# GPIOB_1.0 register map
Vendor: Texas Instruments
Peripheral module from a debugger description file (folder mspm0g1x0x_g3x0x).
Registers are 32-bit, read-write, no defined reset value unless marked. A register's access mark holds for its fields unless they carry their own. Offsets are as the file gives them; lines under a group give offsets from that group; [hi:lo] are bit positions; {n}, {i} and the like mark numbered series; 'fields as' and 'values as' point back to an identical list; <NAME> marks a mode.

## GPIOB
0x400 GPIOB_FSUB_0 — Subsciber Port 0
  [3:0] CHANID — 0 = disconnected. 1-15 = connected to channelID = CHANID.
    0=MNIMUM (0 is an allowed value, signifying that the event is unconnected); 0=UNCONNECTED (A value of 0 specifies that the event is not connected); 15=MAXIMUM (Consult your device datasheet as the actual allowed maximum may be less than 15.)
0x404 GPIOB_FSUB_1 — Subscriber Port 1
  fields as GPIOB_FSUB_0
0x444 GPIOB_FPUB_0 — Publisher Port 0
  fields as GPIOB_FSUB_0
0x448 GPIOB_FPUB_1 — Publisher Port 1
  fields as GPIOB_FSUB_0
0x800 GPIOB_GPRCM group
  0x00 GPIOB_PWREN — Power enable
    [0] ENABLE — Enable the power
      0=DISABLE (Disable Power); 1=ENABLE (Enable Power)
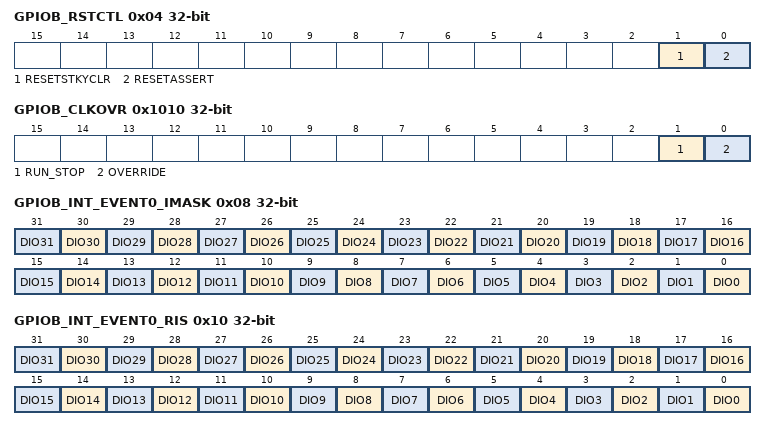
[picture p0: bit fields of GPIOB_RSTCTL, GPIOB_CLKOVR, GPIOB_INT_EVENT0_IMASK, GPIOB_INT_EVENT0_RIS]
  0x04 GPIOB_RSTCTL — Reset Control
    [1] RESETSTKYCLR — Clear the RESETSTKY bit in the STAT register
      0=NOP (Writing 0 has no effect); 1=CLR (Clear reset sticky bit)
    [0] RESETASSERT — Assert reset to the peripheral
      0=NOP (Writing 0 has no effect); 1=ASSERT (Assert reset)
  0x14 GPIOB_STAT ro — Status Register
    [16] RESETSTKY — This bit indicates, if the peripheral was reset, since this bit was cleared by RESETSTKYCLR in the RSTCTL register
      0=NORES (The peripheral has not been reset since this bit was last cleared by RESETSTKYCLR in the RSTCTL register); 1=RESET (The peripheral was reset since the last bit clear)
0x1010 GPIOB_CLKOVR — Clock Override
  [1] RUN_STOP — If [OVERRIDE] is enabled, this register is used to manually control the peripheral's clock request to the system
    0=RUN (Run/ungate functional clock); 1=STOP (Stop/gate functional clock)
  [0] OVERRIDE — Unlocks the functionality of [RUN_STOP] to override the automatic peripheral clock request
    0=DISABLED (Override disabled); 1=ENABLED (Override enabled)
0x1018 GPIOB_PDBGCTL — Peripheral Debug Control
  [0] FREE — Free run control
    0=STOP (The peripheral freezes functionality while the Core Halted input is asserted and resumes when it is deasserted.); 1=RUN (The peripheral ignores the state of the Core Halted input)
0x1020 GPIOB_INT_EVENT0 group
  0x00 GPIOB_INT_EVENT0_IIDX ro — Interrupt index
    [7:0] STAT — Interrupt index status
      0=NO_INTR (No bit is set means there is no pending interrupt request); {v}=DIO{v-1} (DIO{v-1} interrupt) (v=1..32)
  0x08 GPIOB_INT_EVENT0_IMASK — Interrupt mask
    [all] fields
      0=CLR (Event is masked); 1=SET (Event is unmasked)
    [n] DIO{n} (n=0..31) — DIO{n} event mask
  0x10 GPIOB_INT_EVENT0_RIS — Raw interrupt status
    [n] DIO{n} (n=0..31) — DIO{n} event
      0=CLR (DIO{n} event did not occur); 1=SET (DIO{n} event occurred)
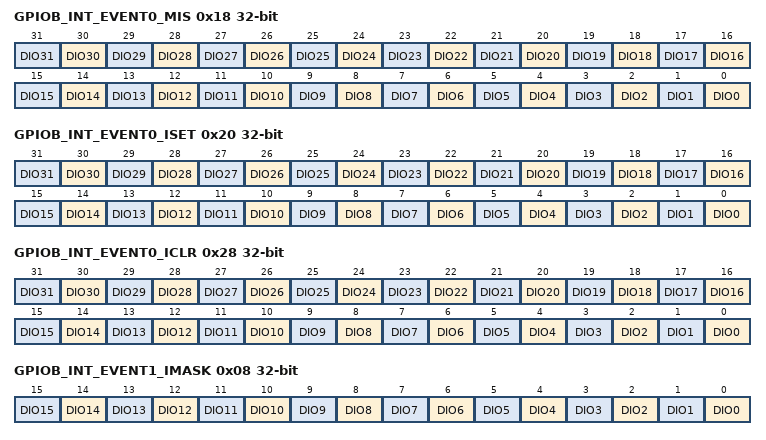
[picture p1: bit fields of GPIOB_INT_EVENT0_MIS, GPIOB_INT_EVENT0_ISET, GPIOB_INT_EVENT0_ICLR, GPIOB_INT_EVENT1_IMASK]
  0x18 GPIOB_INT_EVENT0_MIS — Masked interrupt status
    fields as GPIOB_INT_EVENT0.GPIOB_INT_EVENT0_RIS
  0x20 GPIOB_INT_EVENT0_ISET — Interrupt set
    [n] DIO{n} (n=0..31) — DIO{n} event
      0=NO_EFFECT; 1=SET (Sets DIO{n} in RIS register)
  0x28 GPIOB_INT_EVENT0_ICLR — Interrupt clear
    [n] DIO{n} (n=0..31) — DIO{n} event
      0=NO_EFFECT; 1=CLR (Clears DIO{n} in RIS register)
0x1050 GPIOB_INT_EVENT1 group
  0x00 GPIOB_INT_EVENT1_IIDX ro — Interrupt index
    [7:0] STAT — Interrupt index status
      0=NO_INTR (No bit is set means there is no pending interrupt request); {v}=DIO{v-1} (DIO{v-1} interrupt) (v=1..16)
  0x08 GPIOB_INT_EVENT1_IMASK — Interrupt mask
    [all] fields
      0=CLR (Event is masked); 1=SET (Event is unmasked)
    [n] DIO{n} (n=0..15) — DIO{n} event mask
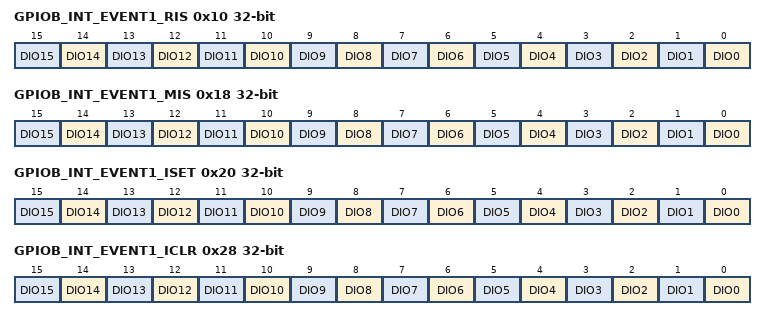
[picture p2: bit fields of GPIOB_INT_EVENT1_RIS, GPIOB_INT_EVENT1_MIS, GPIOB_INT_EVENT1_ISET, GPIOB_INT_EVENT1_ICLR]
  0x10 GPIOB_INT_EVENT1_RIS — Raw interrupt status
    [n] DIO{n} (n=0..15) — DIO{n} event
      values as GPIOB_INT_EVENT0.GPIOB_INT_EVENT0_RIS.DIO0
  0x18 GPIOB_INT_EVENT1_MIS — Masked interrupt status
    fields as GPIOB_INT_EVENT1.GPIOB_INT_EVENT1_RIS
  0x20 GPIOB_INT_EVENT1_ISET — Interrupt set
    [n] DIO{n} (n=0..15) — DIO{n} event
      0=NO_EFFECT; 1=SET (Sets DIO{n} in RIS register)
  0x28 GPIOB_INT_EVENT1_ICLR — Interrupt clear
    [n] DIO{n} (n=0..15) — DIO{n} event
      0=NO_EFFECT; 1=CLR (Clears DIO{n} in RIS register)
0x1080 GPIOB_INT_EVENT2 group
  0x00 GPIOB_INT_EVENT2_IIDX ro — Interrupt index
    [7:0] STAT — Interrupt index status
      0=NO_INTR (No bit is set means there is no pending interrupt request); {v}=DIO{v+15} (DIO{v-1} interrupt) (v=1..16)
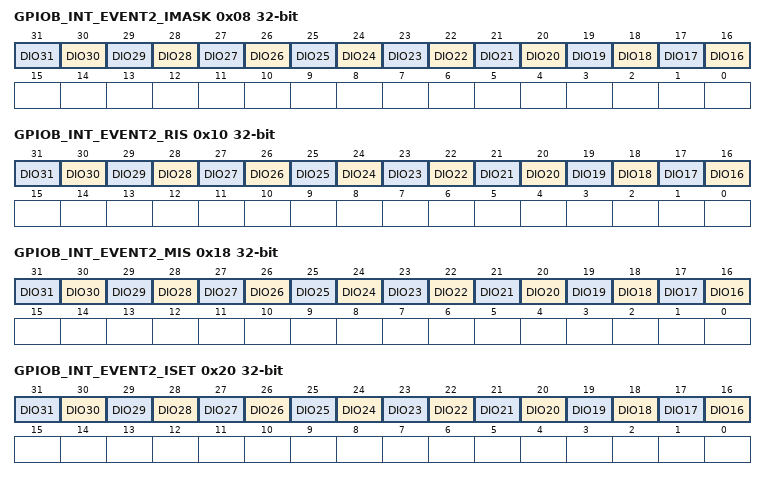
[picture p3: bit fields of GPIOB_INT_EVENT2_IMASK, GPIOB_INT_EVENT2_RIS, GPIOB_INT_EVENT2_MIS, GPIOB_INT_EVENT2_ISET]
  0x08 GPIOB_INT_EVENT2_IMASK — Interrupt mask
    [all] fields
      0=CLR (Event is masked); 1=SET (Event is unmasked)
    [n] DIO{n} (n=16..31) — DIO{n} event mask
  0x10 GPIOB_INT_EVENT2_RIS — Raw interrupt status
    [n] DIO{n} (n=16..31) — DIO{n} event
      values as GPIOB_INT_EVENT0.GPIOB_INT_EVENT0_RIS.DIO0
  0x18 GPIOB_INT_EVENT2_MIS — Masked interrupt status
    fields as GPIOB_INT_EVENT2.GPIOB_INT_EVENT2_RIS
  0x20 GPIOB_INT_EVENT2_ISET — Interrupt set
    [n] DIO{n} (n=16..31) — DIO{n} event
      0=NO_EFFECT; 1=SET (Sets DIO{n} in RIS register)
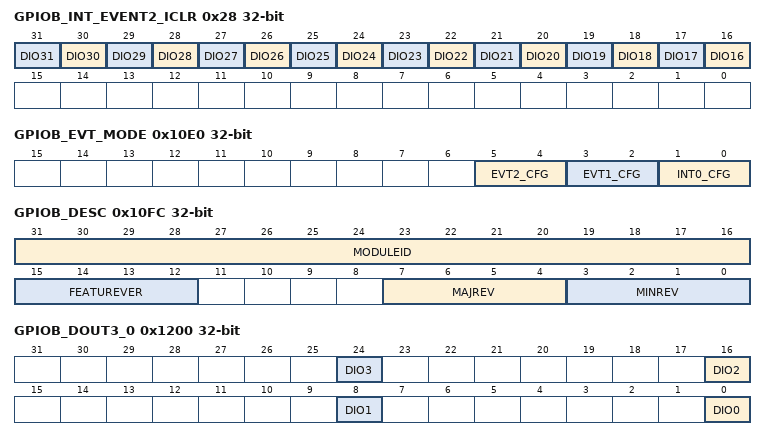
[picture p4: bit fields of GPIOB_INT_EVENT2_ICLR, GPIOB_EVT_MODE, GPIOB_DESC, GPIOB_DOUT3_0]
  0x28 GPIOB_INT_EVENT2_ICLR — Interrupt clear
    [n] DIO{n} (n=16..31) — DIO{n} event
      0=NO_EFFECT; 1=CLR (Clears DIO{n} in RIS register)
0x10E0 GPIOB_EVT_MODE ro — Event Mode
  [all] fields
    0=DISABLE (The interrupt or event line is disabled.); 1=SOFTWARE (The interrupt or event line is in software mode. Software must clear the RIS.); 2=HARDWARE (The interrupt or event line is in hardware mode. The hardware (another module) clears automatically the associated RIS flag.)
  [5:4] EVT2_CFG — Event line mode select for event corresponding to [IPSTANDARD.INT_EVENT2]
  [3:2] EVT1_CFG — Event line mode select for event corresponding to [IPSTANDARD.INT_EVENT1]
  [1:0] INT0_CFG — Event line mode select for event corresponding to [IPSTANDARD.INT_EVENT0]
0x10FC GPIOB_DESC — Module Description
  [31:16] MODULEID — Module identification contains a unique peripheral identification number. The assignments are maintained in a central database for all of the platform modules to ensure uniqueness.
    0=MINIMUM (Smallest value); 0xFFFF=MAXIMUM (Highest possible value)
  [15:12] FEATUREVER — Feature Set for the module *instance*
    0=MINIMUM (Smallest value); 15=MAXIMUM (Highest possible value)
  [7:4] MAJREV — Major rev of the IP
    values as FEATUREVER
  [3:0] MINREV — Minor rev of the IP
    values as FEATUREVER
0x1200 GPIOB_DOUT3_0 — Data output 3 to 0
  [all] fields
    0=ZERO (Output is set to 0); 1=ONE (Output is set to 1)
  [8n] DIO{n} (n=0..3) — This bit sets the value of the pin configured as DIO{n} when the output is enabled through DOE31_0 register.
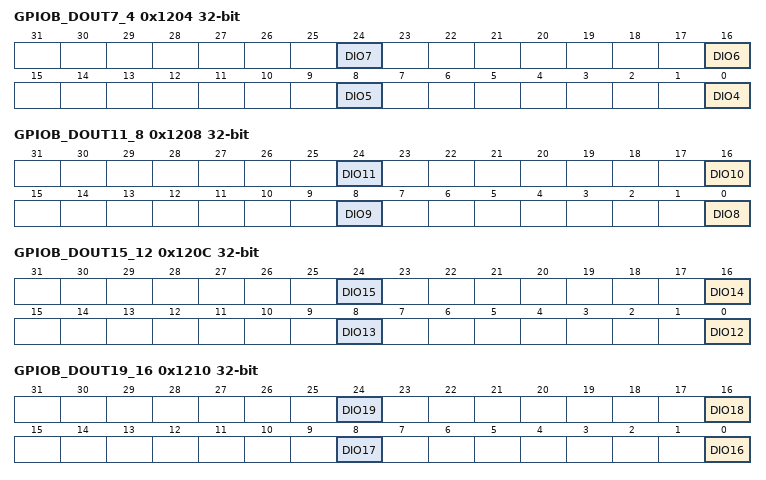
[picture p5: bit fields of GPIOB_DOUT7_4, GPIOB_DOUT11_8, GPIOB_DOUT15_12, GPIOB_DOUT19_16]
0x1204 GPIOB_DOUT7_4 — Data output 7 to 4
  [all] fields
    0=ZERO (Output is set to 0); 1=ONE (Output is set to 1)
  [8n-32] DIO{n} (n=4..7) — This bit sets the value of the pin configured as DIO{n} when the output is enabled through DOE31_0 register.
0x1208 GPIOB_DOUT11_8 — Data output 11 to 8
  [all] fields
    0=ZERO (Output is set to 0); 1=ONE (Output is set to 1)
  [8n-64] DIO{n} (n=8..11) — This bit sets the value of the pin configured as DIO{n} when the output is enabled through DOE31_0 register.
0x120C GPIOB_DOUT15_12 — Data output 15 to 12
  [all] fields
    0=ZERO (Output is set to 0); 1=ONE (Output is set to 1)
  [8n-96] DIO{n} (n=12..15) — This bit sets the value of the pin configured as DIO{n} when the output is enabled through DOE31_0 register.
0x1210 GPIOB_DOUT19_16 — Data output 19 to 16
  [all] fields
    0=ZERO (Output is set to 0); 1=ONE (Output is set to 1)
  [8n-128] DIO{n} (n=16..19) — This bit sets the value of the pin configured as DIO{n} when the output is enabled through DOE31_0 register.
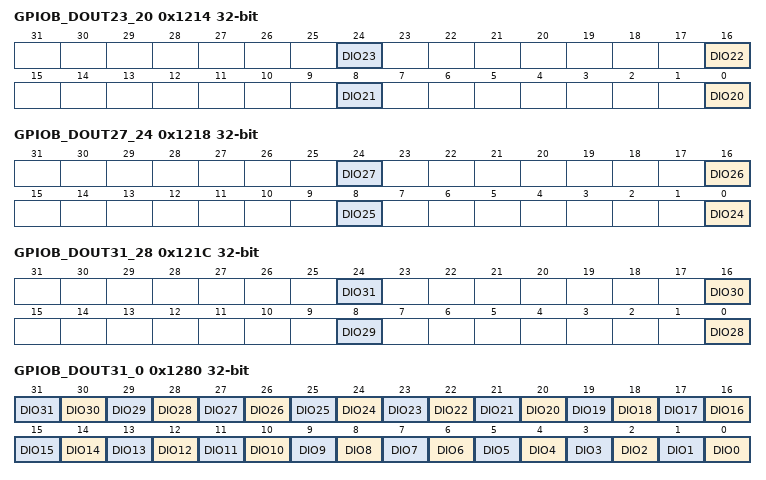
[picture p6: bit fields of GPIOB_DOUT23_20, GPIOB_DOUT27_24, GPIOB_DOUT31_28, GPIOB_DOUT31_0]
0x1214 GPIOB_DOUT23_20 — Data output 23 to 20
  [all] fields
    0=ZERO (Output is set to 0); 1=ONE (Output is set to 1)
  [8n-160] DIO{n} (n=20..23) — This bit sets the value of the pin configured as DIO{n} when the output is enabled through DOE31_0 register.
0x1218 GPIOB_DOUT27_24 — Data output 27 to 24
  [all] fields
    0=ZERO (Output is set to 0); 1=ONE (Output is set to 1)
  [8n-192] DIO{n} (n=24..27) — This bit sets the value of the pin configured as DIO{n} when the output is enabled through DOE31_0 register.
0x121C GPIOB_DOUT31_28 — Data output 31 to 28
  [all] fields
    0=ZERO (Output is set to 0); 1=ONE (Output is set to 1)
  [8n-224] DIO{n} (n=28..31) — This bit sets the value of the pin configured as DIO{n} when the output is enabled through DOE31_0 register.
0x1280 GPIOB_DOUT31_0 — Data output 31 to 0
  [all] fields
    0=ZERO (Output is set to 0); 1=ONE (Output is set to 1)
  [n] DIO{n} (n=0..31) — This bit sets the value of the pin configured as DIO{n} when the output is enabled through DOE31_0 register.
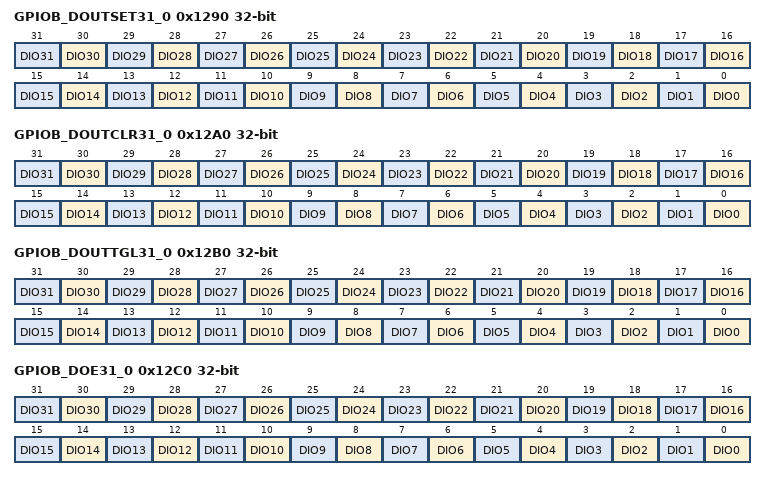
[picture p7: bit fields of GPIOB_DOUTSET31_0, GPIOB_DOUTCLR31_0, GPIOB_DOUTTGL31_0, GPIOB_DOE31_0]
0x1290 GPIOB_DOUTSET31_0 — Data output set 31 to 0
  [n] DIO{n} (n=0..31) — Writing 1 to this bit sets the DIO{n} bit in the DOUT31_0 register. Writing 0 has no effect.
    0=NO_EFFECT; 1=SET (Sets DIO{n} in DOUT31_0)
0x12A0 GPIOB_DOUTCLR31_0 — Data output clear 31 to 0
  [n] DIO{n} (n=0..31) — Writing 1 to this bit clears the DIO{n} bit in the DOUT31_0 register. Writing 0 has no effect.
    0=NO_EFFECT; 1=CLR (Clears DIO{n} in DOUT31_0)
0x12B0 GPIOB_DOUTTGL31_0 — Data output toggle 31 to 0
  [all] fields
    0=NO_EFFECT; 1=TOGGLE (Toggle output)
  [n] DIO{n} (n=0..31) — This bit is used to toggle DIO{n} output.
0x12C0 GPIOB_DOE31_0 — Data output enable 31 to 0
  [all] fields
    0=DISABLE (Output disabled); 1=ENABLE (Output enabled)
  [n] DIO{n} (n=0..31) — Enables data output for DIO{n}.
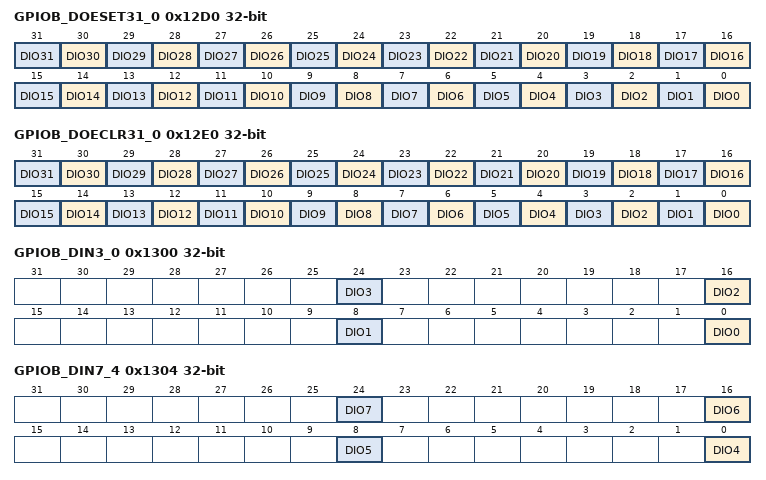
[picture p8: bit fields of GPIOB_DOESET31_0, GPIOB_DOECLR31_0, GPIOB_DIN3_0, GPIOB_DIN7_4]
0x12D0 GPIOB_DOESET31_0 — Data output enable set 31 to 0
  [n] DIO{n} (n=0..31) — Writing 1 to this bit sets the DIO{n} bit in the DOE31_0 register. Writing 0 has no effect.
    0=NO_EFFECT; 1=SET (Sets DIO{n} in DOE31_0)
0x12E0 GPIOB_DOECLR31_0 — Data output enable clear 31 to 0
  [n] DIO{n} (n=0..31) — Writing 1 to this bit clears the DIO{n} bit in the DOE31_0 register. Writing 0 has no effect.
    0=NO_EFFECT; 1=CLR (Clears DIO{n} in DOE31_0)
0x1300 GPIOB_DIN3_0 ro — Data input 3 to 0
  [all] fields
    0=ZERO (Input value is 0); 1=ONE (Input value is 1)
  [8n] DIO{n} (n=0..3) — This bit reads the data input value of DIO{n}.
0x1304 GPIOB_DIN7_4 ro — Data input 7 to 4
  [all] fields
    0=ZERO (Input value is 0); 1=ONE (Input value is 1)
  [8n-32] DIO{n} (n=4..7) — This bit reads the data input value of DIO{n}.
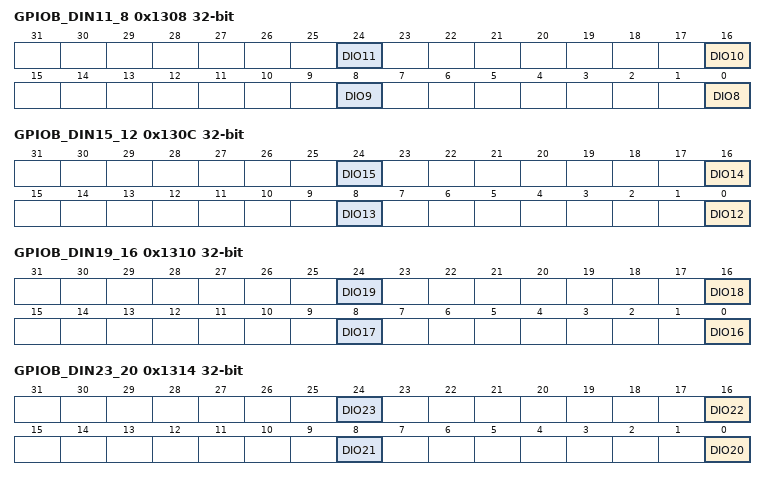
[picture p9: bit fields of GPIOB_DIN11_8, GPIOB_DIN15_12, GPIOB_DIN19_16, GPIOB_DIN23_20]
0x1308 GPIOB_DIN11_8 ro — Data input 11 to 8
  [all] fields
    0=ZERO (Input value is 0); 1=ONE (Input value is 1)
  [8n-64] DIO{n} (n=8..11) — This bit reads the data input value of DIO{n}.
0x130C GPIOB_DIN15_12 ro — Data input 15 to 12
  [all] fields
    0=ZERO (Input value is 0); 1=ONE (Input value is 1)
  [8n-96] DIO{n} (n=12..15) — This bit reads the data input value of DIO{n}.
0x1310 GPIOB_DIN19_16 ro — Data input 19 to 16
  [all] fields
    0=ZERO (Input value is 0); 1=ONE (Input value is 1)
  [8n-128] DIO{n} (n=16..19) — This bit reads the data input value of DIO{n}.
0x1314 GPIOB_DIN23_20 ro — Data input 23 to 20
  [all] fields
    0=ZERO (Input value is 0); 1=ONE (Input value is 1)
  [8n-160] DIO{n} (n=20..23) — This bit reads the data input value of DIO{n}.
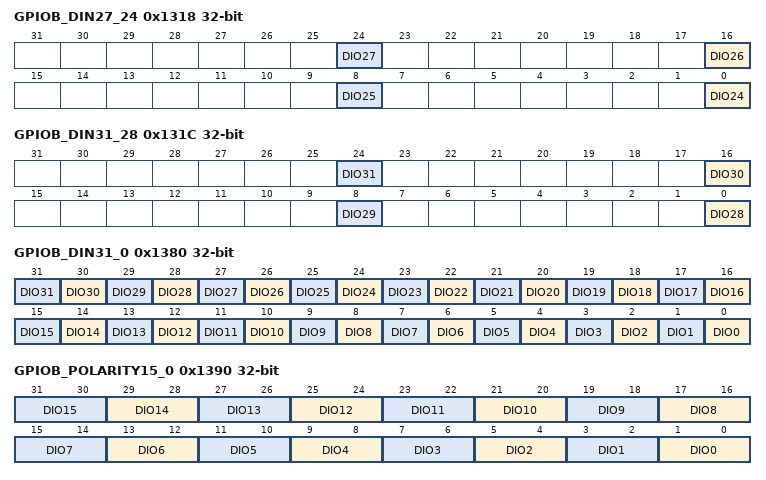
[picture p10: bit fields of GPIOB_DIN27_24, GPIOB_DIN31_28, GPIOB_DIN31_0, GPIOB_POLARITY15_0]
0x1318 GPIOB_DIN27_24 ro — Data input 27 to 24
  [all] fields
    0=ZERO (Input value is 0); 1=ONE (Input value is 1)
  [8n-192] DIO{n} (n=24..27) — This bit reads the data input value of DIO{n}.
0x131C GPIOB_DIN31_28 ro — Data input 31 to 28
  [all] fields
    0=ZERO (Input value is 0); 1=ONE (Input value is 1)
  [8n-224] DIO{n} (n=28..31) — This bit reads the data input value of DIO{n}.
0x1380 GPIOB_DIN31_0 ro — Data input 31 to 0
  [all] fields
    0=ZERO (Input value is 0); 1=ONE (Input value is 1)
  [n] DIO{n} (n=0..31) — This bit reads the data input value of DIO{n}.
0x1390 GPIOB_POLARITY15_0 — Polarity 15 to 0
  [all] fields
    0=DISABLE (Edge detection disabled); 1=RISE (Detects rising edge of input event); 2=FALL (Detects falling edge of input event); 3=RISE_FALL (Detects both rising and falling edge of input event)
  [2n+1:2n] DIO{n} (n=0..15) — Enables and configures edge detection polarity for DIO{n}.
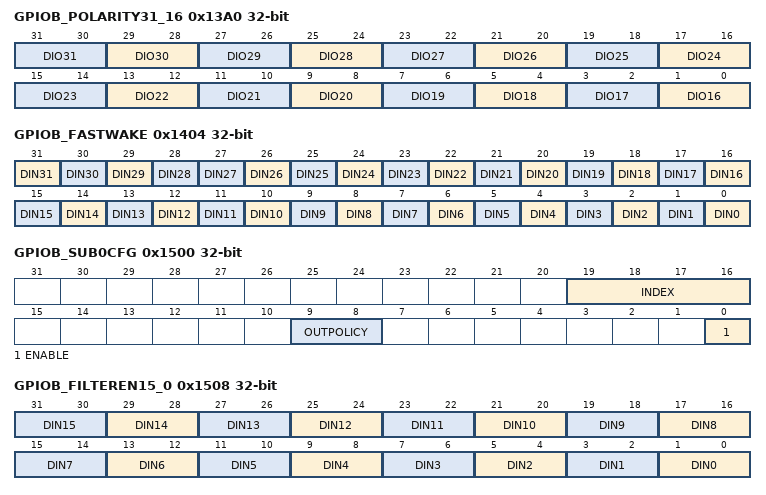
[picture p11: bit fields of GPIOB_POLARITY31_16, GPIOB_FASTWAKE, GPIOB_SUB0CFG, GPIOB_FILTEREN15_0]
0x13A0 GPIOB_POLARITY31_16 — Polarity 31 to 16
  [all] fields
    values as the fields of GPIOB_POLARITY15_0
  [2n-31:2n-32] DIO{n} (n=16..31) — Enables and configures edge detection polarity for DIO{n}.
0x1400 GPIOB_CTL — FAST WAKE GLOBAL EN
  [0] FASTWAKEONLY — FASTWAKEONLY for the global control of fastwake
    0=NOT_GLOBAL_EN (The global control of fastwake is not enabled, per bit fast wake feature depends on FASTWAKE.DIN); 1=GLOBAL_EN (The global control of fastwake is enabled)
0x1404 GPIOB_FASTWAKE — FAST WAKE ENABLE
  [all] fields
    0=DISABLE (fastwake feature is disabled); 1=ENABLE (fastwake feature is enabled)
  [31] DIN31 — Enable fastwake feature for DIN31
  [30] DIN30 — Enable fastwake feature for DIN30
  [29] DIN29 — Enable fastwake feature for DIN29
  [28] DIN28 — Enable fastwake feature for DIN29
  [n] DIN{n} (n=0..27) — Enable fastwake feature for DIN{n}
0x1500 GPIOB_SUB0CFG — Subscriber 0 configuration
  [19:16] INDEX — Indicates the specific bit among lower 16 bits that is targeted by the subscriber action
    0=MIN (specific bit targeted by the subscriber action is bit0); 15=MAX (specific bit targeted by the subscriber action is bit15)
  [9:8] OUTPOLICY — These bits configure the output policy for subscriber 0 event.
    0=SET (Selected DIO pins are set); 1=CLR (Selected DIO pins are cleared); 2=TOGGLE (Selected DIO pins are toggled)
  [0] ENABLE — This bit is used to enable subscriber 0 event.
    0=CLR (Subscriber 0 event is disabled); 1=SET (Subscriber 0 event is enabled)
0x1508 GPIOB_FILTEREN15_0 — Filter Enable 15 to 0
  [all] fields
    0=DISABLE (No additional filter beyond the CDC synchronization sample); 1=ONE_CYCLE (1 ULPCLK minimum sample); 2=THREE_CYCLE (3 ULPCLK minimum sample); 3=EIGHT_CYCLE (8 ULPCLK minimum sample)
  [2n+1:2n] DIN{n} (n=0..15) — Programmable counter length of digital glitch filter for DIN{n}
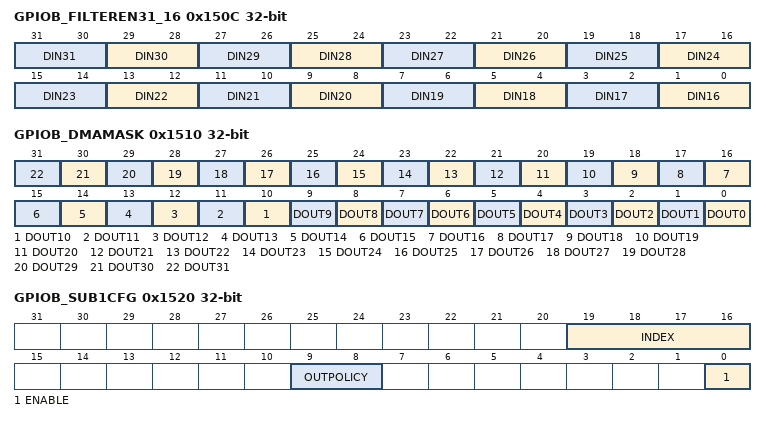
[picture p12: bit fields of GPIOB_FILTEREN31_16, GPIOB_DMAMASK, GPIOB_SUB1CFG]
0x150C GPIOB_FILTEREN31_16 — Filter Enable 31 to 16
  [all] fields
    values as the fields of GPIOB_FILTEREN15_0
  [2n-31:2n-32] DIN{n} (n=16..31) — Programmable counter length of digital glitch filter for DIN{n}
0x1510 GPIOB_DMAMASK — DMA Write MASK
  [all] fields
    0=DISABLE (DMA is not allowed to modify this bit lane); 1=ENABLE (DMA is allowed to modify this bit lane)
  [n] DOUT{n} (n=0..31) — DMA is allowed to modify DOUT{n}
0x1520 GPIOB_SUB1CFG — Subscriber 1 configuration
  [19:16] INDEX — indicates the specific bit in the upper 16 bits that is targeted by the subscriber action
    0=MIN (specific bit targeted by the subscriber action is bit16); 15=MAX (specific bit targeted by the subscriber action is bit31)
  [9:8] OUTPOLICY — These bits configure the output policy for subscriber 1 event.
    values as GPIOB_SUB0CFG.OUTPOLICY
  [0] ENABLE — This bit is used to enable subscriber 1 event.
    0=CLR (Subscriber 1 event is disabled); 1=SET (Subscriber 1 event is enabled)
